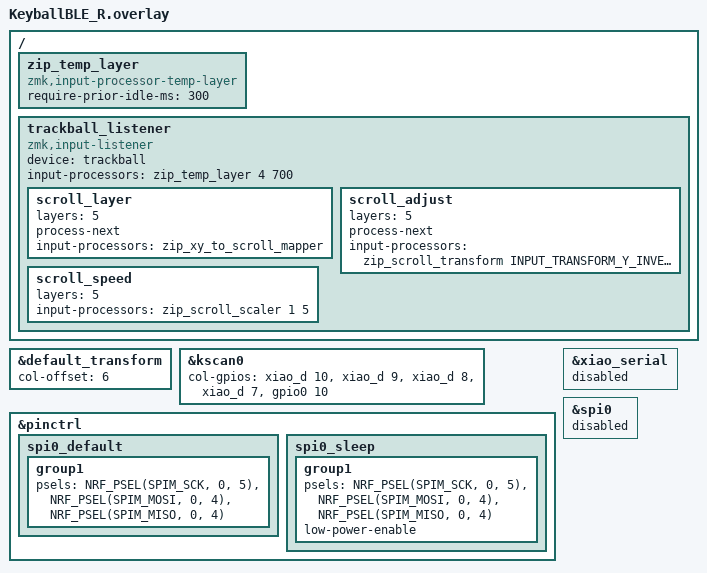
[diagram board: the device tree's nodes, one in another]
#include "KeyballBLE.dtsi"
#include <zephyr/dt-bindings/input/input-event-codes.h>
#include <input/processors.dtsi>
#include <dt-bindings/zmk/input_transform.h>

&default_transform {
    col-offset = <6>;
};

&kscan0 {
    col-gpios
        = <&xiao_d 10 GPIO_ACTIVE_HIGH>
        , <&xiao_d 9 GPIO_ACTIVE_HIGH>
        , <&xiao_d 8 GPIO_ACTIVE_HIGH>
        , <&xiao_d 7 GPIO_ACTIVE_HIGH>
        , <&gpio0 10 GPIO_ACTIVE_HIGH>
        ;
};

/ {
    /omit-if-no-ref/ zip_temp_layer: zip_temp_layer {
        compatible = "zmk,input-processor-temp-layer";
        #input-processor-cells = <2>;
        require-prior-idle-ms = <300>;
    };

    trackball_listener: trackball_listener {
        compatible = "zmk,input-listener";
        device = <&trackball>;
        input-processors = <&zip_temp_layer 4 700>;

        scroll_layer {
            layers = <5>;
            process-next;
            input-processors = <&zip_xy_to_scroll_mapper>;
        };

        scroll_adjust {
            layers = <5>;
            process-next;
            input-processors = <&zip_scroll_transform INPUT_TRANSFORM_Y_INVERT>;
        };

        scroll_speed {
            layers = <5>;
            input-processors = <&zip_scroll_scaler 1 5>;
        };
    };
};

&pinctrl {
    spi0_default: spi0_default {
        group1 {
            psels = <NRF_PSEL(SPIM_SCK, 0, 5)>,
                    <NRF_PSEL(SPIM_MOSI, 0, 4)>,
                    <NRF_PSEL(SPIM_MISO, 0, 4)>;
        };
    };

    spi0_sleep: spi0_sleep {
        group1 {
            psels = <NRF_PSEL(SPIM_SCK, 0, 5)>,
                    <NRF_PSEL(SPIM_MOSI, 0, 4)>,
                    <NRF_PSEL(SPIM_MISO, 0, 4)>;
            low-power-enable;
        };
    };
};

&xiao_serial {
    status = "disabled";
};

&spi0 {
    status = "disabled";
};
